# Qorvo_SVD register map
Vendor: Qorvo Inc; Series: ARMCM4; File version: 1.0
Registers are 8-bit, read-write, reset 0x0 unless marked. A register's access mark holds for its fields unless they carry their own. Offsets are from the block's base; [hi:lo] are bit positions; <NAME> marks a mode.

## I2C_SL
Base 0x400011E0
0x02 I2C_SL_SLAVE_ADDRESS 16-bit reset 0x4E
  [9:0] SLAVE_ADDRESS — I2C slave address
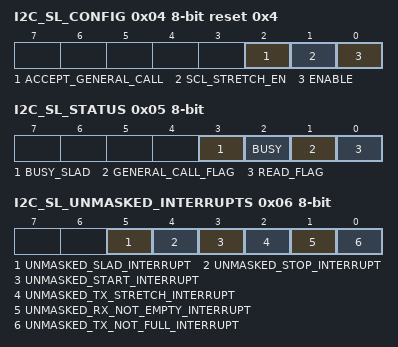
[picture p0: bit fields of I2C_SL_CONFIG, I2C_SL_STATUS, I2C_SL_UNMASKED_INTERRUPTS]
0x04 I2C_SL_CONFIG reset 0x4
  [2] ACCEPT_GENERAL_CALL — Enable slave selection via the general call address.
  [1] SCL_STRETCH_EN — Enable clock stretching by the slave.
  [0] ENABLE — Enable core when '1'
0x05 I2C_SL_STATUS ro
  [3] BUSY_SLAD — When 1, the slave is currently selected, an I2C transfer is busy. Set upon a SLAD event, cleared upon a STOP event.
  [2] BUSY — When 1, an I2C transfer is busy Set upon a START event, cleared upon a STOP event.
  [1] GENERAL_CALL_FLAG — Status of the address match of the last successful slave addressing . When 0, the slave was selected by its own address. When 1, the slave was selected by the general call address (= all 0). The flag is updated on each slad event.
  [0] READ_FLAG — Status of the RnW bit of the last successful slave addressing. When 0, this indicated master-to-slave direction. When 0, this indicated slave-to-master direction. The flag is updated on each slad event.
0x06 I2C_SL_UNMASKED_INTERRUPTS ro
  [5] UNMASKED_SLAD_INTERRUPT — Event and unmasked interrupt flag for the occurrence of a SLAD event (slave addressed). Set when this slave has been (re-)selected or upon a general call. Cleared explicitly by the SW.
  [4] UNMASKED_STOP_INTERRUPT — Event and unmasked interrupt flag for the occurrence of a STOP condition on the I2C bus. Set when the STOP condition is detected. Cleared explicitly by the SW.
  [3] UNMASKED_START_INTERRUPT — Event and unmasked interrupt flag for the occurrence of a START condition on the I2C bus. Set when a START or a repeated START condition is detected. Cleared explicitly by the SW.
  [2] UNMASKED_TX_STRETCH_INTERRUPT — Status and unmasked interrupt flag for SCL stretching ongoing. The interrupt is active when SCL is being stretched by the slave. SCL stretching occurs when scl_stretch_en = '1', the slave has been successfully addressed in read direction, and the tx_data FIFO is empty. This interrupt can be used to trigger writes to tx_data.
  [1] UNMASKED_RX_NOT_EMPTY_INTERRUPT — Status and unmasked interrupt flag for RX buffer not empty. The interrupt is cleared implicitly when reading the last RX data from the buffer.
  [0] UNMASKED_TX_NOT_FULL_INTERRUPT — Status and unmasked interrupt flag for TX buffer not full. The interrupt is set when TX data is ready to accept new bytes.

## I2S_M
Base 0x40001300
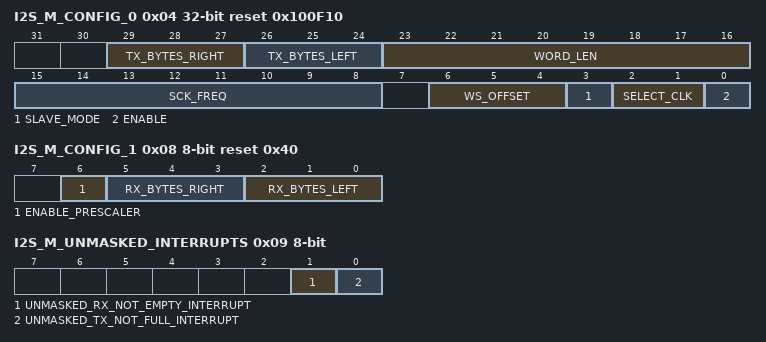
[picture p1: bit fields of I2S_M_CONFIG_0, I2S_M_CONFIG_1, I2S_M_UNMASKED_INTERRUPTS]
0x04 I2S_M_CONFIG_0 32-bit reset 0x100F10
  [29:27] TX_BYTES_RIGHT — Number of data bytes to be transmitted on SDO for the right channel (WS=1). Same remarks as for tx_bytes_left.
  [26:24] TX_BYTES_LEFT — Number of data bytes (8-bit) to be transmitted on SDO for the left channel (WS=0). When word_len > 8*tx_bytes_left, SDO will be padded with 0. When word_len < 8*tx_bytes_left, the remaining bits (lsbs) will be ignored. If tx_bytes_left = 0, SDO will be 0 for this channel.
  [23:16] WORD_LEN — Length in SCK cycles between two consecutive WS toggles.
  [15:8] SCK_FREQ — SCK bit clock frequency prescaler: processing_clk_freq / 2*(sck_freq + 1)
  [6:4] WS_OFFSET — Offset in SCK cycles between the WS toggle and the first data bit. For real I2S mode, this should be 1.
  [3] SLAVE_MODE — Enables the slave mode. When false, the interface is in master mode.
  [2:1] SELECT_CLK — Selects the processing clock of the interface.
  [0] ENABLE — Starts the interface. Make sure the first databyte is already available in tx_data before enabling the interface.
0x08 I2S_M_CONFIG_1 reset 0x40
  [6] ENABLE_PRESCALER — Enables the SCK clock prescaler. Only applicable when select_clk /= MAIN_CLK. The prescaler is always enabled when select_clk = MAIN_CLK.
  [5:3] RX_BYTES_RIGHT — Number of data bytes (8-bit) to be received on SDI for the right channel (WS=1). Same remarks as for rx_bytes_left.
  [2:0] RX_BYTES_LEFT — Number of data bytes (8-bit) to be received on SDI for the left channel (WS=0). When word_len > 8*tx_bytes_left, the remaining bits on SDI will be ignored. When word_len < 8*tx_bytes_left, the remaining bits (lsbs) will be zero. If tx_bytes_left = 0, no data will be received for this channel.
0x09 I2S_M_UNMASKED_INTERRUPTS ro
  [1] UNMASKED_RX_NOT_EMPTY_INTERRUPT — Status and unmasked interrupt flag for RX buffer not empty. The interrupt is cleared implicitly when reading the last RX data from the buffer.
  [0] UNMASKED_TX_NOT_FULL_INTERRUPT — Status and unmasked interrupt flag for TX buffer not full. The interrupt is cleared implicitly when writing new TX data fills the buffer.

## ASP
Base 0x40001320
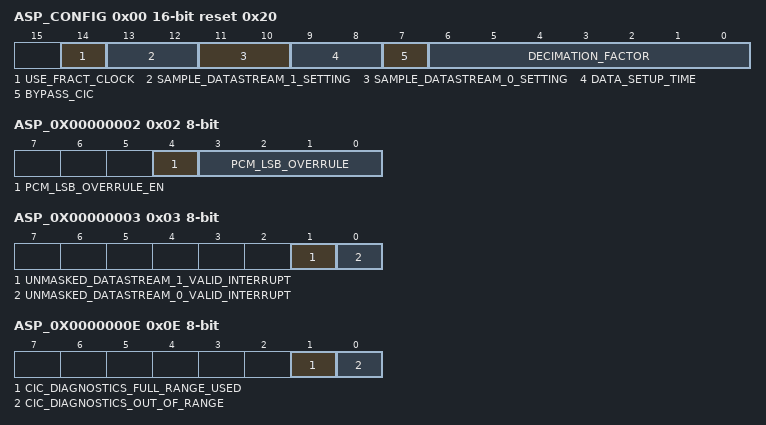
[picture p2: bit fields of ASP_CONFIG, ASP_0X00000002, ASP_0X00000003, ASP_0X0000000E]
0x00 ASP_CONFIG 16-bit reset 0x20
  [14] USE_FRACT_CLOCK — If set: use the fractional clock (see bbpll regmap). If not set: a 2MHz clk will be generated
  [13:12] SAMPLE_DATASTREAM_1_SETTING — Enable capturing data on specified mode on the dut
  [11:10] SAMPLE_DATASTREAM_0_SETTING — Enable capturing data on specified mode on the dut
  [9:8] DATA_SETUP_TIME — Number of 16 MHz periods after a rising/falling edge before the data is stable (nr_periods = value + 1)
  [7] BYPASS_CIC — Don't filter the streams but convert them into a 16-bit word stream that can be read from the data register (lsb is the bit first received)
  [6:0] DECIMATION_FACTOR — Factor-1 with which the incoming pdm signal should be downsampled (actual decimation factor = value+1)
0x02 ASP_0X00000002
  [4] PCM_LSB_OVERRULE_EN — Use pcm_lsb_overrule value
  [3:0] PCM_LSB_OVERRULE — Sets the 16 bits to shift out of the (24 bit) pcm stream coming from the cic filter and into the data_out registers, when not overruled this is the value determined of theoretical max value
0x03 ASP_0X00000003 ro
  [1] UNMASKED_DATASTREAM_1_VALID_INTERRUPT — Data is available from the data_1 register, is indirectly cleared by reading out the data
  [0] UNMASKED_DATASTREAM_0_VALID_INTERRUPT — Data is available from the data_0 register, is indirectly cleared by reading out the data
0x0C ASP_0X0000000C
  [0] CLK_2M_ENABLE — Enable the 2MHz clock.
0x0E ASP_0X0000000E ro
  [1] CIC_DIAGNOSTICS_FULL_RANGE_USED — Flag indicating that the CIC filter was using its full range at least once since the last time the flags were cleared
  [0] CIC_DIAGNOSTICS_OUT_OF_RANGE — Flag indicating that the CIC filter went out of range at least once since the last time the flags were cleared
